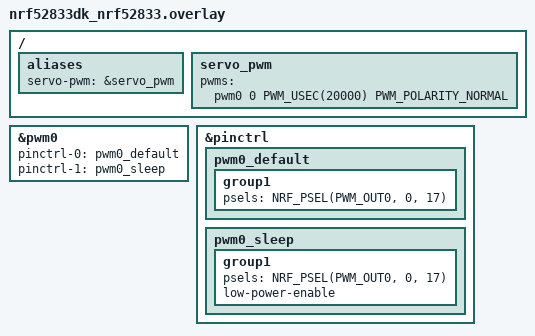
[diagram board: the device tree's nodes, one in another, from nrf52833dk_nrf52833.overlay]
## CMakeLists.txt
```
<<<<<<< HEAD
#
# Copyright (c) 2018 Nordic Semiconductor
#
# SPDX-License-Identifier: LicenseRef-Nordic-5-Clause
#
cmake_minimum_required(VERSION 3.20.0)

find_package(Zephyr REQUIRED HINTS $ENV{ZEPHYR_BASE})
project(peripheral_lbs)

# NORDIC SDK APP START
target_sources(app PRIVATE
  src/main.c
)

# NORDIC SDK APP END
=======
cmake_minimum_required(VERSION 3.20.0)
find_package(Zephyr REQUIRED HINTS $ENV{ZEPHYR_BASE})

project(blink_test)

target_sources(app PRIVATE src/main.c)
>>>>>>> 8ac7c7586f60419b73b2e1f6d33a28ed7058a853
```

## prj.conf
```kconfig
CONFIG_LOG=y
CONFIG_LOG_DEFAULT_LEVEL=3
CONFIG_GPIO=y
CONFIG_BT=y
CONFIG_BT_PERIPHERAL=y
CONFIG_BT_DEVICE_NAME="Dog Treat Dispenser"
CONFIG_BT_MAX_CONN=1
CONFIG_PWM=y
```

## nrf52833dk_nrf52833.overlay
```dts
#include <zephyr/dt-bindings/pinctrl/nrf-pinctrl.h>
#include <zephyr/dt-bindings/pwm/pwm.h>

/ {
    aliases {
        servo-pwm = &servo_pwm;
    };

    servo_pwm: servo_pwm {
        pwms = <&pwm0 0 PWM_USEC(20000) PWM_POLARITY_NORMAL>;
    };
};

&pwm0 {
    status = "okay";
    pinctrl-0 = <&pwm0_default>;
    pinctrl-1 = <&pwm0_sleep>;
    pinctrl-names = "default", "sleep";
};

&pinctrl {
    pwm0_default: pwm0_default {
        group1 {
            psels = <NRF_PSEL(PWM_OUT0, 0, 17)>;
        };
    };

    pwm0_sleep: pwm0_sleep {
        group1 {
            psels = <NRF_PSEL(PWM_OUT0, 0, 17)>;
            low-power-enable;
        };
    };
};
```

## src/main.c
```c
#include <zephyr/kernel.h>
#include <zephyr/bluetooth/bluetooth.h>
#include <zephyr/bluetooth/conn.h>
#include <bluetooth/services/lbs.h>
#include <dk_buttons_and_leds.h>
#include <zephyr/settings/settings.h>
#include <zephyr/drivers/pwm.h> 

#define USER_LED DK_LED1
#define DEVICE_NAME "Dog_treat_dispenser"

// Get the servo pin mapping from the device tree
static const struct pwm_dt_spec servo = PWM_DT_SPEC_GET(DT_NODELABEL(servo));

/* 
 * SG90 Servo pulse widths define the angle of the motor arm.
 * 600 microseconds = ~45 degrees (Closed lid)
 * 2400 microseconds = ~135 degrees (Open lid)
 */
#define SERVO_CLOSED_PULSE PWM_USEC(600) 
#define SERVO_OPEN_PULSE   PWM_USEC(2400) 


static bool is_connected;
static bool is_advertising;
static bool command_flash;
static bool led_blink_state;
static int command_phase;
static bool servo_stop_phase;
static uint32_t servo_target_pulse; // Stores the requested open/close angle

// Handles the visual status lights without freezing the Bluetooth radio.
static void led_work_handler(struct k_work *work);
static K_WORK_DELAYABLE_DEFINE(led_work, led_work_handler);

// Waits 1 second after a phone disconnects before turning the radio back on.
static void restart_advertising_work_handler(struct k_work *work);
static K_WORK_DELAYABLE_DEFINE(restart_advertising_work, restart_advertising_work_handler);

// Servo Motor Task
static struct k_work_delayable servo_work;

// Bluetooth advertising
static const struct bt_data ad[] = {
    BT_DATA_BYTES(BT_DATA_FLAGS, (BT_LE_AD_GENERAL | BT_LE_AD_NO_BREDR)),
    BT_DATA(BT_DATA_NAME_COMPLETE, DEVICE_NAME, (sizeof(DEVICE_NAME) - 1)),
};


static void connected(struct bt_conn *conn, uint8_t err)
{
    if (err) {
        printk("Connection failed: %u\n", err);
        return;
    }

    printk("Bluetooth connected\n");

    // Update state
    is_connected = true;
    is_advertising = false;

    // Cancel any pending background task so they don't interfere with the new connection
    k_work_cancel_delayable(&restart_advertising_work);
    k_work_cancel_delayable(&led_work);

    // Turn the LED on solid to confirm connection
    dk_set_led(USER_LED, 1);
}

// Runs automatically when the phone disconnects
static void disconnected(struct bt_conn *conn, uint8_t reason)
{
    printk("Bluetooth disconnected, reason: %u\n", reason);

    is_connected = false;
    is_advertising = false;

    dk_set_led(USER_LED, 0);

    k_work_reschedule(&restart_advertising_work, K_SECONDS(1));
}

// Register the connection callbacks with the Zephyr Bluetooth stack
BT_CONN_CB_DEFINE(conn_callbacks) = {
    .connected = connected,
    .disconnected = disconnected,
};

// Controls the LED states
static void led_work_handler(struct k_work *work)
{
    ARG_UNUSED(work);

    // Acknowledge a command from the phone by flashing LED
    if (command_flash) {
        if (command_phase == 0) {
            dk_set_led(USER_LED, 0); 
            command_phase = 1;
            k_work_reschedule(&led_work, K_MSEC(500));
        } else if (command_phase == 1) {
            dk_set_led(USER_LED, 1);
            command_phase = 2;
            k_work_reschedule(&led_work, K_MSEC(500));
        } else {
            command_flash = false;
            command_phase = 0;
            k_work_reschedule(&led_work, K_NO_WAIT);
        }
        return;
    }

    // Normal connection status
    if (is_connected) {
        dk_set_led(USER_LED, 1);
    } else if (is_advertising) {
        led_blink_state = !led_blink_state;
        dk_set_led(USER_LED, led_blink_state);
        k_work_reschedule(&led_work, K_MSEC(500));
    } else {
        dk_set_led(USER_LED, 0);
    }
}

// Controls the servo motor
static void servo_work_handler(struct k_work *work)
{
    ARG_UNUSED(work);

    if (!servo_stop_phase) {
        // Send the PWM signal to start moving the motor
        int err = pwm_set_pulse_dt(&servo, servo_target_pulse);
        if (err) {
            printk("Servo PWM start failed (err %d)\n", err);
            servo_stop_phase = false;
            return;
        }

        // Set a 500ms timer to give the time to turn
        servo_stop_phase = true;
        k_work_reschedule(&servo_work, K_MSEC(500));

    } else {
        int err = pwm_set_pulse_dt(&servo, 0);
        if (err) {
            printk("Servo PWM stop failed (err %d)\n", err);
        }

        servo_stop_phase = false;
    }
}

// Commands the Bluetooth to start broadcasting
static void restart_advertising_work_handler(struct k_work *work)
{
    ARG_UNUSED(work);

    int err = bt_le_adv_start(BT_LE_ADV_CONN_FAST_2, ad, ARRAY_SIZE(ad), NULL, 0);

    if (err == 0) {
        printk("Advertising restarted successfully\n");
        is_advertising = true;
        led_blink_state = false;
        k_work_reschedule(&led_work, K_NO_WAIT);
    } else if (err == -EALREADY) {
        printk("Advertising is already active\n");
        is_advertising = true;
    } else {
        printk("Advertising restart failed: %d\n", err);
        k_work_reschedule(&restart_advertising_work, K_SECONDS(1));
    }
}


// Bluetooth command task
static void app_led_cb(bool led_state)
{
    printk("Command received: %s\n", led_state ? "OPEN" : "CLOSE");

    command_flash = true;
    command_phase = 0;
    k_work_reschedule(&led_work, K_NO_WAIT);

    // 2. Choose the correct angle based on the bluetooth command
    servo_target_pulse = led_state ? SERVO_OPEN_PULSE : SERVO_CLOSED_PULSE;

    servo_stop_phase = false;
    k_work_reschedule(&servo_work, K_NO_WAIT);
}

static struct bt_lbs_cb lbs_callbacks = {
    .led_cb = app_led_cb
};


int main(void) {
    dk_leds_init();

    if (!pwm_is_ready_dt(&servo)) {
        printk("Error: PWM device is not ready\n");
        return 0;
    }

    k_work_init_delayable(&servo_work, servo_work_handler);

    // Turn on the Bluetooth
    bt_enable(NULL);
    settings_load();

    bt_lbs_init(&lbs_callbacks);

    int err = bt_le_adv_start(BT_LE_ADV_CONN_FAST_2, ad, ARRAY_SIZE(ad), NULL, 0);
    if (err) {
        printk("Advertising failed (err %d)\n", err);
        return 0;
    }

    is_advertising = true;
    is_connected = false;
    led_blink_state = false;

    k_work_reschedule(&led_work, K_NO_WAIT);

    printk("Broadcasting...\n");
    
    return 0;
}
```

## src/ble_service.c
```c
#include "ble_service.h"

#include <errno.h>
#include <stdbool.h>
#include <stdint.h>

#include <zephyr/kernel.h>
#include <zephyr/logging/log.h>
#include <zephyr/bluetooth/bluetooth.h>
#include <zephyr/bluetooth/conn.h>
#include <zephyr/bluetooth/gatt.h>

#include "servo.h"
#include "status_led.h"

LOG_MODULE_REGISTER(ble_service, LOG_LEVEL_INF);

/*
 * Custom 128-bit UUIDs for the dispenser service
 * and hatch-control characteristic.
 */
#define BT_UUID_DOG_DISPENSER_VAL \
    BT_UUID_128_ENCODE(0x7E400001, 0xB5A3, 0xF393, \
                       0xE0A9, 0xE50E24DCCA9E)

#define BT_UUID_HATCH_CONTROL_VAL \
    BT_UUID_128_ENCODE(0x7E400002, 0xB5A3, 0xF393, \
                       0xE0A9, 0xE50E24DCCA9E)

static struct bt_uuid_128 dog_dispenser_uuid =
    BT_UUID_INIT_128(BT_UUID_DOG_DISPENSER_VAL);

static struct bt_uuid_128 hatch_control_uuid =
    BT_UUID_INIT_128(BT_UUID_HATCH_CONTROL_VAL);

/*
 * Handle a phone writing to the Hatch Control characteristic.
 *
 * Expected command:
 *   0x01 = toggle hatch
 */
static ssize_t hatch_control_write(
    struct bt_conn *conn,
    const struct bt_gatt_attr *attr,
    const void *buf,
    uint16_t len,
    uint16_t offset,
    uint8_t flags)
{
    ARG_UNUSED(conn);
    ARG_UNUSED(attr);
    ARG_UNUSED(flags);

    /* This characteristic accepts one byte at offset zero. */
    if (offset != 0 || len != 1) {
        return BT_GATT_ERR(BT_ATT_ERR_INVALID_ATTRIBUTE_LEN);
    }

    const uint8_t *data = buf;

    if (data[0] != 0x01) {
        return BT_GATT_ERR(BT_ATT_ERR_VALUE_NOT_ALLOWED);
    }

    LOG_INF("Hatch toggle command received");

    /*
     * The LED acknowledges receipt of a valid command.
     * This does not mean the physical hatch has moved.
     */
    status_led_command_flash();

    /*
     * Request the servo action.
     * The servo stub currently returns -ENOTSUP because
     * hardware-specific PWM has not been implemented.
     */
    int ret = servo_toggle();

    if (ret < 0) {
        LOG_WRN("Hatch action failed: %d", ret);
    }

    /*
     * The command was valid and accepted by this callback.
     * Return the number of bytes consumed, even if the
     * servo implementation is still a hardware stub.
     */
    return len;
}

/*
 * Register the service and its writable characteristic.
 */
BT_GATT_SERVICE_DEFINE(dog_dispenser_service,
    BT_GATT_PRIMARY_SERVICE(&dog_dispenser_uuid),

    BT_GATT_CHARACTERISTIC(
        &hatch_control_uuid.uuid,
        BT_GATT_CHRC_WRITE,
        BT_GATT_PERM_WRITE,
        NULL,
        hatch_control_write,
        NULL
    )
);

/*
 * Advertising data: discoverable, connectable BLE peripheral.
 */
static const struct bt_data advertising_data[] = {
    BT_DATA_BYTES(BT_DATA_FLAGS,
        (BT_LE_AD_GENERAL | BT_LE_AD_NO_BREDR)),
};

/*
 * Put the full device name in the scan response.
 * This avoids making the advertising packet too large.
 */
static const struct bt_data scan_response_data[] = {
    BT_DATA(BT_DATA_NAME_COMPLETE,
        CONFIG_BT_DEVICE_NAME,
        sizeof(CONFIG_BT_DEVICE_NAME) - 1),
};

/*
 * Start BLE advertising.
 */
static int start_advertising(void)
{
    int ret = bt_le_adv_start(
        BT_LE_ADV_CONN_FAST_1,
        advertising_data,
        ARRAY_SIZE(advertising_data),
        scan_response_data,
        ARRAY_SIZE(scan_response_data)
    );

    if (ret < 0) {
        LOG_ERR("Failed to start advertising: %d", ret);
        return ret;
    }

    LOG_INF("BLE advertising started");

    status_led_set_state(STATUS_LED_ADVERTISING);

    return 0;
}

/*
 * Called when a phone connects.
 */
static void connected(struct bt_conn *conn, uint8_t err)
{
    ARG_UNUSED(conn);

    if (err != 0) {
        LOG_WRN("Connection failed: 0x%02x", err);
        return;
    }

    LOG_INF("Phone connected");

    status_led_set_state(STATUS_LED_CONNECTED);
}

/*
 * Called when the phone disconnects.
 */
static void disconnected(struct bt_conn *conn, uint8_t reason)
{
    ARG_UNUSED(conn);

    LOG_INF("Phone disconnected: 0x%02x", reason);

    /*
     * Return to advertising so the phone can reconnect.
     */
    int ret = start_advertising();

    if (ret < 0) {
        LOG_ERR("Could not restart advertising: %d", ret);
    }
}

BT_CONN_CB_DEFINE(connection_callbacks) = {
    .connected = connected,
    .disconnected = disconnected,
};

/*
 * Public initialization function.
 */
int ble_service_init(void)
{
    int ret = bt_enable(NULL);

    if (ret < 0) {
        LOG_ERR("Bluetooth initialization failed: %d", ret);
        return ret;
    }

    LOG_INF("Bluetooth initialized");

    ret = start_advertising();

    if (ret < 0) {
        return ret;
    }

    return 0;
}
```

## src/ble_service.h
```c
#ifndef BLE_SERVICE_H
#define BLE_SERVICE_H

/*
 * Initialize Bluetooth, register the custom GATT service,
 * and start advertising so a phone can find the device.
 *
 * Returns 0 on success, or a negative error code on failure.
 */
int ble_service_init(void);

#endif /* BLE_SERVICE_H */
```

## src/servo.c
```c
#include "servo.h"

#include <errno.h>

#include <zephyr/logging/log.h>

LOG_MODULE_REGISTER(servo, LOG_LEVEL_INF);

/*
 * Software state.
 *
 * Initially, assume the hatch is closed.
 * This is only an assumption until the physical
 * hatch position can be established.
 */
static bool hatch_open = false;

/*
 * Hardware placeholder.
 *
 * Later, this module will configure PWM and send
 * the appropriate control signal to the servo.
 */
int servo_init(void)
{
    LOG_INF("Initializing servo module");

    /*
     * TODO:
     * 1. Get the PWM device from devicetree.
     * 2. Check that the PWM device is ready.
     * 3. Configure the servo control output.
     *
     * No physical servo is controlled yet.
     */

    LOG_WRN("Servo hardware is not configured");

    return -ENOTSUP;
}

int servo_open(void)
{
    LOG_INF("Open requested");

    /*
     * TODO:
     * Command the servo to the calibrated
     * open position.
     *
     * Do not update hatch_open until the
     * command has been accepted.
     */

    LOG_WRN("Servo movement is not implemented");

    return -ENOTSUP;
}

int servo_close(void)
{
    LOG_INF("Close requested");

    /*
     * TODO:
     * Command the servo to the calibrated
     * closed position.
     */

    LOG_WRN("Servo movement is not implemented");

    return -ENOTSUP;
}

int servo_toggle(void)
{
    if (hatch_open) {
        return servo_close();
    }

    return servo_open();
}

bool servo_is_open(void)
{
    return hatch_open;
}
```

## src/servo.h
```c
#ifndef SERVO_H
#define SERVO_H

#include <stdbool.h>

/*
 * Initialize the servo module.
 *
 * Returns 0 on success, or a negative error code on failure.
 */
int servo_init(void);

/* Request the hatch to open. */
int servo_open(void);

/* Request the hatch to close. */
int servo_close(void);

/* Toggle between open and closed. */
int servo_toggle(void);

/* Return the last commanded hatch state. */
bool servo_is_open(void);

#endif /* SERVO_H */
```

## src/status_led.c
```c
#include "status_led.h"

#include <errno.h>

#include <zephyr/kernel.h>
#include <zephyr/drivers/gpio.h>
#include <zephyr/logging/log.h>
#include <zephyr/devicetree.h>

LOG_MODULE_REGISTER(status_led, LOG_LEVEL_INF);

/*
 * Use the first LED defined by the board's devicetree.
 * For the nRF52833 DK, this is normally LED1 on the board.
 */
static const struct gpio_dt_spec status_led =
    GPIO_DT_SPEC_GET(DT_ALIAS(led0), gpios);

/* Timing values in milliseconds. */
#define BLINK_INTERVAL_MS 500
#define COMMAND_FLASH_MS  150

/* Current normal operating state. */
static status_led_state_t current_state = STATUS_LED_BOOT;

/* True while the temporary command flash is active. */
static bool flash_active;

/* Current physical output level: 0 = off, 1 = on. */
static bool led_on;

/* Work items allow timed LED changes without busy-waiting. */
static struct k_work_delayable blink_work;
static struct k_work_delayable flash_work;

/*
 * Apply a physical LED output level.
 */
static void led_write(bool on)
{
    int ret = gpio_pin_set_dt(&status_led, on ? 1 : 0);

    if (ret < 0) {
        LOG_ERR("Failed to set status LED: %d", ret);
        return;
    }

    led_on = on;
}

/*
 * Return the LED to the normal operating state.
 */
static void apply_normal_state(void)
{
    if (flash_active) {
        return;
    }

    switch (current_state) {
    case STATUS_LED_BOOT:
        (void)k_work_cancel_delayable(&blink_work);
        led_write(false);
        break;

    case STATUS_LED_ADVERTISING:
        /*
         * Begin the advertising pattern.
         * The work handler will toggle the LED.
         */
        led_write(true);
        (void)k_work_reschedule(
            &blink_work,
            K_MSEC(BLINK_INTERVAL_MS));
        break;

    case STATUS_LED_CONNECTED:
        (void)k_work_cancel_delayable(&blink_work);
        led_write(true);
        break;

    default:
        (void)k_work_cancel_delayable(&blink_work);
        led_write(false);
        break;
    }
}

/*
 * Blink handler.
 */
static void blink_work_handler(struct k_work *work)
{
    ARG_UNUSED(work);

    if (flash_active ||
        current_state != STATUS_LED_ADVERTISING) {
        return;
    }

    led_write(!led_on);

    (void)k_work_reschedule(
        &blink_work,
        K_MSEC(BLINK_INTERVAL_MS));
}

/*
 * End the temporary command flash.
 */
static void flash_work_handler(struct k_work *work)
{
    ARG_UNUSED(work);

    flash_active = false;
    apply_normal_state();
}

/*
 * Initialize GPIO and delayed work.
 */
int status_led_init(void)
{
    if (!gpio_is_ready_dt(&status_led)) {
        LOG_ERR("Status LED GPIO device is not ready");
        return -ENODEV;
    }

    int ret = gpio_pin_configure_dt(
        &status_led,
        GPIO_OUTPUT_INACTIVE);

    if (ret < 0) {
        LOG_ERR("Failed to configure status LED: %d", ret);
        return ret;
    }

    k_work_init_delayable(
        &blink_work,
        blink_work_handler);

    k_work_init_delayable(
        &flash_work,
        flash_work_handler);

    current_state = STATUS_LED_BOOT;
    flash_active = false;
    led_on = false;

    led_write(false);

    LOG_INF("Status LED initialized");

    return 0;
}

/*
 * Change the normal operating state.
 */
void status_led_set_state(status_led_state_t state)
{
    current_state = state;

    /*
     * A new connection state should cancel any
     * temporary command flash.
     */
    flash_active = false;
    (void)k_work_cancel_delayable(&flash_work);

    apply_normal_state();
}

/*
 * Briefly turn the LED on to acknowledge a command.
 */
void status_led_command_flash(void)
{
    flash_active = true;

    /*
     * Pause the advertising blink while the flash
     * is active. The normal state is preserved.
     */
    (void)k_work_cancel_delayable(&blink_work);

    led_write(true);

    (void)k_work_reschedule(
        &flash_work,
        K_MSEC(COMMAND_FLASH_MS));
}
```

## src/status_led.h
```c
#ifndef STATUS_LED_H
#define STATUS_LED_H

/*
 * LED states for the dog treat dispenser.
 */
typedef enum {
    STATUS_LED_BOOT,
    STATUS_LED_ADVERTISING,
    STATUS_LED_CONNECTED
} status_led_state_t;

/*
 * Initialize the status LED hardware.
 *
 * Returns 0 on success, negative error on failure.
 */
int status_led_init(void);

/*
 * Set the normal operating state of the LED.
 */
void status_led_set_state(status_led_state_t state);

/*
 * Flash the LED briefly when a hatch command
 * is received and accepted.
 */
void status_led_command_flash(void);

#endif /* STATUS_LED_H */
```
